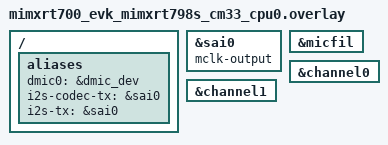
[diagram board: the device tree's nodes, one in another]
/*
 * Copyright 2025 NXP
 *
 * SPDX-License-Identifier: Apache-2.0
 */

/ {
	aliases {
		dmic0 = &dmic_dev;
		i2s-codec-tx = &sai0;
		i2s-tx = &sai0;
	};
};

&sai0 {
	mclk-output;
};

dmic_dev: &micfil {
	status = "okay";
};

&channel0 {
	status = "okay";
};

&channel1 {
	status = "okay";
};
